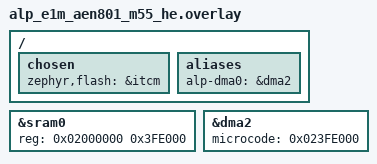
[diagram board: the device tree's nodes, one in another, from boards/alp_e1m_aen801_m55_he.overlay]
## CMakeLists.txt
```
# SPDX-License-Identifier: Apache-2.0
#
# aen-dma-regcheck -- on-silicon validation of the ARM PL330 DMA controller on
# the E1M-AEN801 (Alif Ensemble E8, M55-HE), via the bench RAM-run + RAM-console
# flow.  Unlike the bind-only *-regcheck siblings, this app runs a REAL
# memory-to-memory copy through the PL330 and verifies the bytes (the PL330 needs
# no external pins).
#
# The PL330 driver is UPSTREAM Zephyr v4.4's drivers/dma/dma_pl330.c
# (compatible "arm,dma-pl330") -- ADR 0017 Tier-1 (upstream-native), no vendored
# code.  CONFIG_DMA + CONFIG_DMA_PL330 (prj.conf) build it in once the dma2 node
# is enabled by the board overlay.  The overlay enables dma2, defines the
# alp_dma0 alias, points the PL330 `microcode` scratch at global SRAM0, and
# carves the source/destination buffers into SRAM0 (the PL330 AXI master cannot
# reach the M55's DTCM).
#
# The board overlay boards/alp_e1m_aen801_m55_he_ae822fa0e5597ls0_rtss_he.overlay auto-applies for the
# fully-qualified board (alp_e1m_aen801_m55_he/ae822fa0e5597ls0/rtss_he).  Build:
#   ZEPHYR_BASE=<zephyr-base> west build \
#     -b alp_e1m_aen801_m55_he/ae822fa0e5597ls0/rtss_he <this-dir> -- \
#     "-DEXTRA_ZEPHYR_MODULES=<alp-sdk>;<hal_alif>"

cmake_minimum_required(VERSION 3.20)

find_package(Zephyr REQUIRED HINTS $ENV{ZEPHYR_BASE})
project(aen_dma_regcheck LANGUAGES C)

target_sources(app PRIVATE src/main.c)
```

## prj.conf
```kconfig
# SPDX-License-Identifier: Apache-2.0
#
# Bench config for the DMA regcheck on the E1M-AEN801 (M55-HE).  The console is
# the E1M edge UART0 (Alif UART5, P3_4/P3_5, 115200 8N1); serial-less benches
# can fall back to the RAM console (see the console block below).

# DMA subsystem + the UPSTREAM ARM PL330 driver.  CONFIG_DMA makes the dma_*
# class available; CONFIG_DMA_PL330 is `default y if DT_HAS_ARM_DMA_PL330_ENABLED`
# (drivers/dma/Kconfig.dma_pl330) so the upstream dma_pl330.c TU builds in once
# the dma2 node is enabled by the board overlay.  ADR 0017 Tier-1 -- pure
# upstream, no ALP_SDK gating needed for the driver itself.
CONFIG_DMA=y
CONFIG_DMA_PL330=y

# 32-bit address path: the M55 + the PL330 register set are 32-bit, and the
# buffers/microcode live in the 32-bit-addressable global SRAM0 window.  Leave
# CONFIG_DMA_64BIT off (its default) so the driver does NOT require a
# `control_regs` reg-by-name on the node (that 36-bit AXI-add-control window is
# not declared here).
# CONFIG_DMA_64BIT is not set

# Coherency: the PL330 AXI master and the M55 must share ONE view of the SRAM0
# buffers + microcode with no cache maintenance.  CONFIG_DCACHE=n matches the
# eth_dwmac / NPU DMA-buffers-in-SRAM0 finding (the upstream PL330 driver issues
# no cache clean/invalidate around the transfer).
CONFIG_DCACHE=n

# Console: Alp UART console -- E1M edge UART0 (Alif UART5, P3_4/P3_5, 115200
# 8N1, NS16550), the E1M-AEN801 carrier console. The board _defconfig already
# selects it; we set it explicitly here so the example is self-describing.
CONFIG_SERIAL=y
CONFIG_CONSOLE=y
CONFIG_UART_CONSOLE=y
CONFIG_UART_INTERRUPT_DRIVEN=y
# Serial-less bench? Comment the four lines above and uncomment these to read
# 'ram_console_buf' over SWD instead:
# CONFIG_RAM_CONSOLE=y
# CONFIG_RAM_CONSOLE_BUFFER_SIZE=2048
# CONFIG_UART_CONSOLE=n
CONFIG_PRINTK=y

# Keep the image small + deterministic for a RAM-run.
CONFIG_LOG=n
```

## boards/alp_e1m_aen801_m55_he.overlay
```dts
/*
 * Copyright (c) 2026 Alp Lab AB
 * SPDX-License-Identifier: Apache-2.0
 *
 * aen-dma-regcheck board overlay for the E1M-AEN801 (Ensemble E8, M55-HE)
 * RAM-run.  Enables the ARM PL330 DMA controller (dma2) that the E8 SoC overlay
 * (zephyr/dts/alif/ensemble_e8_peripherals.dtsi) declares status=disabled, binds
 * the alp_dma0 portable alias to it, gives the PL330 a real `microcode` scratch
 * address in global SRAM0, and reserves that SRAM0 carve-out so it cannot
 * collide with the source/destination buffers.
 *
 * ====================  DMA REACHABILITY: GLOBAL SRAM0 ONLY  ==================
 * The PL330 is an AXI bus master.  It fetches its generated per-channel
 * microcode AND reads/writes the copy buffers over its OWN AXI master, so EVERY
 * address it touches must be GLOBAL (AXI-visible).  The M55's DTCM (local
 * 0x20000000, where the generated board puts default RAM) is core-private and is
 * NOT on the DMA path.  So:
 *
 *   - the buffers (src_buf/dst_buf) are tagged section("SRAM0") in main.c, which
 *     lands them in the sram0 linker region @0x02000000 (global on-chip SRAM);
 *   - the PL330 `microcode` scratch is pointed at a carve-out at the TOP of that
 *     same 4 MiB bank.
 *
 * Unlike the NPU/eth paths, the UPSTREAM PL330 driver does NO Alif local->global
 * remap -- it programs the addresses verbatim -- so the addresses the CPU hands
 * it (the &src_buf/&dst_buf in SRAM0, and this `microcode` base) ARE the global
 * addresses the engine fetches.  Combined with CONFIG_DCACHE=n (prj.conf) the
 * CPU and DMA share one coherent view.
 *
 * SRAM0 CARVE-OUT (sram0 node = 0x02000000, DT_SIZE_M(4) = 0x400000):
 *   - microcode region : top 8 KiB = 0x023FE000 .. 0x02400000
 *                        (8 channels * MICROCODE_SIZE_MAX 0x400 = 0x2000, the
 *                         minimum the PL330 driver carves -- dma_pl330.h);
 *   - buffers (SRAM0)  : the sram0 node is SHRUNK to 0x02000000 + 0x3FE000
 *                        (4 MiB - 8 KiB) so the linker keeps src_buf/dst_buf
 *                        strictly BELOW the microcode region -- no overlap.
 * ============================================================================
 */

/ {
	/*
	 * MANDATORY bench RAM-run retarget (Flow C): run from ITCM so J-Link can
	 * loadbin+go without programming MRAM, and drop the MCUboot code-partition
	 * fixup.  Same setup as the sibling *-regcheck examples.
	 *
	 * PATH-REFERENCE form (&itcm), NOT the <&itcm> phandle-array form: the
	 * phandle-array form yields CONFIG_FLASH_SIZE=0 and the image overflows the
	 * (empty) FLASH region at link time.
	 */
	chosen {
		zephyr,flash = &itcm;
		/delete-property/ zephyr,code-partition;
	};

	aliases {
		/* The alp portable DMA alias resolves bus 0 via DT_ALIAS(alp_dma0). */
		alp-dma0 = &dma2;
	};
};

/*
 * Shrink the global SRAM0 region by the top 8 KiB so the PL330 microcode
 * carve-out (0x023FE000..0x02400000) never overlaps the section("SRAM0")
 * buffers.  Base stays 0x02000000; size 0x400000 - 0x2000 = 0x3FE000.
 */
&sram0 {
	reg = <0x02000000 0x3FE000>;
};

&dma2 {
	/*
	 * Real microcode scratch base: top 8 KiB of SRAM0 (global, AXI-visible),
	 * just above the shrunk sram0 region.  The PL330 driver carves this into
	 * 8 * 0x400 B per-channel ucode slots (dma_pl330_initialize()).
	 */
	microcode = <0x023FE000>;
	status = "okay";
};
```

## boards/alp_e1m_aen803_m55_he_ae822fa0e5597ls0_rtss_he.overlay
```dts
/*
 * Copyright (c) 2026 Alp Lab AB
 * SPDX-License-Identifier: Apache-2.0
 *
 * aen-dma-regcheck board overlay for the E1M-AEN803 (Ensemble E8, M55-HE)
 * RAM-run.  Enables the ARM PL330 DMA controller (dma2) that the E8 SoC overlay
 * (zephyr/dts/alif/ensemble_e8_peripherals.dtsi) declares status=disabled, binds
 * the alp_dma0 portable alias to it, gives the PL330 a real `microcode` scratch
 * address in global SRAM0, and reserves that SRAM0 carve-out so it cannot
 * collide with the source/destination buffers.
 *
 * ====================  DMA REACHABILITY: GLOBAL SRAM0 ONLY  ==================
 * The PL330 is an AXI bus master.  It fetches its generated per-channel
 * microcode AND reads/writes the copy buffers over its OWN AXI master, so EVERY
 * address it touches must be GLOBAL (AXI-visible).  The M55's DTCM (local
 * 0x20000000, where the generated board puts default RAM) is core-private and is
 * NOT on the DMA path.  So:
 *
 *   - the buffers (src_buf/dst_buf) are tagged section("SRAM0") in main.c, which
 *     lands them in the sram0 linker region @0x02000000 (global on-chip SRAM);
 *   - the PL330 `microcode` scratch is pointed at a carve-out at the TOP of that
 *     same 4 MiB bank.
 *
 * Unlike the NPU/eth paths, the UPSTREAM PL330 driver does NO Alif local->global
 * remap -- it programs the addresses verbatim -- so the addresses the CPU hands
 * it (the &src_buf/&dst_buf in SRAM0, and this `microcode` base) ARE the global
 * addresses the engine fetches.  Combined with CONFIG_DCACHE=n (prj.conf) the
 * CPU and DMA share one coherent view.
 *
 * SRAM0 CARVE-OUT (sram0 node = 0x02000000, DT_SIZE_M(4) = 0x400000):
 *   - microcode region : top 8 KiB = 0x023FE000 .. 0x02400000
 *                        (8 channels * MICROCODE_SIZE_MAX 0x400 = 0x2000, the
 *                         minimum the PL330 driver carves -- dma_pl330.h);
 *   - buffers (SRAM0)  : the sram0 node is SHRUNK to 0x02000000 + 0x3FE000
 *                        (4 MiB - 8 KiB) so the linker keeps src_buf/dst_buf
 *                        strictly BELOW the microcode region -- no overlap.
 * ============================================================================
 */

/ {
	/*
	 * MANDATORY bench RAM-run retarget (Flow C): run from ITCM so J-Link can
	 * loadbin+go without programming MRAM, and drop the MCUboot code-partition
	 * fixup.  Same setup as the sibling *-regcheck examples.
	 *
	 * PATH-REFERENCE form (&itcm), NOT the <&itcm> phandle-array form: the
	 * phandle-array form yields CONFIG_FLASH_SIZE=0 and the image overflows the
	 * (empty) FLASH region at link time.
	 */
	chosen {
		zephyr,flash = &itcm;
		/delete-property/ zephyr,code-partition;
	};

	aliases {
		/* The alp portable DMA alias resolves bus 0 via DT_ALIAS(alp_dma0). */
		alp-dma0 = &dma2;
	};
};

/*
 * Shrink the global SRAM0 region by the top 8 KiB so the PL330 microcode
 * carve-out (0x023FE000..0x02400000) never overlaps the section("SRAM0")
 * buffers.  Base stays 0x02000000; size 0x400000 - 0x2000 = 0x3FE000.
 */
&sram0 {
	reg = <0x02000000 0x3FE000>;
};

&dma2 {
	/*
	 * Real microcode scratch base: top 8 KiB of SRAM0 (global, AXI-visible),
	 * just above the shrunk sram0 region.  The PL330 driver carves this into
	 * 8 * 0x400 B per-channel ucode slots (dma_pl330_initialize()).
	 */
	microcode = <0x023FE000>;
	status = "okay";
};
```

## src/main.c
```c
/*
 * Copyright (c) 2026 Alp Lab AB
 * SPDX-License-Identifier: Apache-2.0
 *
 * aen-dma-regcheck -- on-silicon validation of the ARM PL330 DMA controller on
 * the E1M-AEN801 (Ensemble E8, M55-HE), via the bench RAM-run + RAM-console
 * flow.  Unlike the bind-only *-regcheck siblings (CAN/camera/ISP, which are
 * HW-blocked on missing wiring), this app performs a REAL memory-to-memory copy:
 * the PL330 needs no external pins or transceiver, so it actually runs the DMA
 * and verifies the bytes landed.
 *
 * ===========================  WHAT THIS VALIDATES  ==========================
 *   1. The dma2 DT node binds to UPSTREAM Zephyr's ARM PL330 driver
 *      (drivers/dma/dma_pl330.c, compatible "arm,dma-pl330") at the E8's
 *      core-local secure DMA2 base 0x400C0000 -- pure ADR 0017 Tier-1
 *      (upstream-native): the standard Zephyr dma_* class device, no vendored
 *      or forked code.
 *   2. The alp portable alias alp_dma0 resolves to that same node.
 *   3. The driver INSTANTIATES (DEVICE_DT_GET resolves, device_is_ready()).
 *   4. A real M2M transfer COPIES the bytes: dma_config(MEMORY_TO_MEMORY) +
 *      dma_start(), then a memcmp() of source vs destination.
 *
 * The upstream PL330 driver is a POLLING engine: dma_pl330_transfer_start()
 * calls dma_pl330_submit() -> dma_pl330_xfer() -> dma_pl330_wait(), which spins
 * on the channel-status CS0 register until the channel goes idle.  So when
 * dma_start() RETURNS 0 the copy has already completed -- no interrupt and no
 * completion callback are needed (and the binding declares no `interrupts`).
 * That is why this app verifies synchronously right after dma_start().
 *
 * ====================  THE #1 BENCH RISK: DMA REACHABILITY  =================
 * The PL330 is an AXI bus master.  It fetches its generated channel microcode
 * AND reads/writes the source/destination buffers over its OWN AXI master, so
 * EVERY address it touches must be a GLOBAL (AXI-visible) address -- NOT a
 * core-local TCM alias.  The M55's default RAM (.bss/.noinit) on the generated
 * board lands in DTCM (local 0x20000000), which the DMA AXI master cannot see.
 *
 * Fix (mirrors the eth_dwmac DMA-buffers-in-SRAM0 + the NPU arena-in-SRAM0
 * findings): src_buf/dst_buf are tagged into the "SRAM0" linker region -- global
 * on-chip SRAM @0x02000000 -- and the board overlay points the PL330 `microcode`
 * scratch at a carve-out in that same bank.  Combined with CONFIG_DCACHE=n
 * (prj.conf) the CPU and the DMA share one coherent view with no cache
 * maintenance.  If the buffers were left in DTCM the copy would read/write
 * garbage or fault; placing them in global SRAM0 is what makes the transfer
 * real.  See the board overlay header for the carve-out addresses.
 * ============================================================================
 */

#include <stdbool.h>
#include <stdint.h>
#include <string.h>

#include <zephyr/kernel.h>
#include <zephyr/device.h>
#include <zephyr/devicetree.h>
#include <zephyr/drivers/dma.h>
#include <zephyr/sys/printk.h>
#include <zephyr/sys/sys_io.h>

/* The PL330 controller node + the alp portable alias that must point at it. */
#define DMA_NODE  DT_NODELABEL(dma2)
#define DMA_ALIAS DT_ALIAS(alp_dma0)

/* Channel 0 of the 8 PL330 execution channels (dma-channels = <8>). */
#define DMA_CHANNEL 0U

/* Transfer size.  Deliberately not a multiple of the burst length so the
 * driver's residual-tail path is exercised too. */
#define XFER_LEN 1000U

/*
 * Expected facts, transcribed from the SoC dtsi (which carries the Alif AE822
 * DFP addresses) so a binding that resolved to the wrong node is caught.
 *
 *   reg base 0x400C0000 -- DMA2_SEC_BASE (DFP rtss_he/soc.h)
 *   dma-channels 8      -- PL330 execution channels (DFP DMA_*_CHANNEL_*[8])
 */
#define DMA_BASE_EXPECTED     0x400C0000U
#define DMA_CHANNELS_EXPECTED 8U

/*
 * Source + destination buffers MUST be in global, AXI-visible SRAM0 (see the
 * file + overlay headers): the PL330 AXI master cannot reach the M55's DTCM.
 * The "SRAM0" section is the sram0 node's linker region (@0x02000000).
 */
static uint8_t src_buf[XFER_LEN] __attribute__((section("SRAM0")));
static uint8_t dst_buf[XFER_LEN] __attribute__((section("SRAM0")));

/*
 * Compile-time staging fact: the node exists, is enabled, and binds to the
 * upstream PL330 compatible.
 */
#define DMA_BOUND \
	(DT_NODE_HAS_STATUS(DMA_NODE, okay) && DT_NODE_HAS_COMPAT(DMA_NODE, arm_dma_pl330))

/* The alp_dma0 alias must resolve to the SAME node the PL330 driver binds. */
#define ALIAS_OK (DT_NODE_EXISTS(DMA_ALIAS) && (DT_DEP_ORD(DMA_ALIAS) == DT_DEP_ORD(DMA_NODE)))

int main(void)
{
	printk("\n=== aen-dma-regcheck ===\n");

	/*
	 * Alif E8 prelude: DMA2 is the M55-core-LOCAL DMA.  The upstream
	 * arm,dma-pl330 driver is SoC-agnostic and never touches the Alif system-
	 * control block, so before it can run we have to do here exactly what the
	 * Alif CMSIS DMA driver does in its power-up path (DFP Driver_DMA.c
	 * DMA_PowerControl ARM_POWER_FULL, case DMA_INSTANCE_LOCAL):
	 *
	 *   (1) dmalocal_enable_periph_clk()        CLK_ENA   |= BIT(4)
	 *   (2) dmalocal_set_boot_manager_secure()  DMA_CTRL  &= ~BIT(0)   (0 = secure)
	 *   (3) dmalocal_set_boot_irq_ns_mask(0)    DMA_IRQ    = 0
	 *   (4) dmalocal_set_boot_periph_ns_mask(0) DMA_PERIPH = 0
	 *   (5) dmalocal_reset()                    DMA_CTRL  |= BIT(16)   (SW_RST)
	 *
	 * These registers live in the per-core M55_CFG_Common block.  On the M55-HE
	 * that block IS M55HE_CFG (DFP rtss_he/core_defines.h:
	 * M55LOCAL_CFG == (M55_CFG_Common_Type *)M55HE_CFG_BASE).  Clean-room values
	 * transcribed from the DFP (proprietary; values only, not source):
	 *   M55HE_CFG_BASE        0x43007000  -- DFP rtss_he/soc.h
	 *   DMA_CTRL    @ +0x00 |   DMA_IRQ @ +0x04 |  DMA_PERIPH @ +0x08
	 *   DMA_SEL     @ +0x0C |   CLK_ENA @ +0x10   -- DFP M55_CFG_Common_Type
	 *                                                (rtss_he/core_defines.h)
	 *   CLK_ENA_DMA_CKEN      BIT(4)       -- DFP drivers/include/sys_ctrl_dma.h
	 *   DMA_CTRL_BOOT_MANAGER BIT(0)  0=Secure 1=Non-Secure -- DFP sys_ctrl_dma.h
	 *   DMA_CTRL_SW_RST       BIT(16)      -- DFP drivers/include/sys_ctrl_dma.h
	 * Boot IRQ / boot peripheral non-secure masks are 0 (RTE_DMA2_BOOT_IRQ_NS_STATE
	 * / RTE_DMA2_BOOT_PERIPH_NS_STATE == 0 for AE822, DFP soc/AE822.../rte/
	 * RTE_Device.h) -- everything stays in the secure domain, matching the secure
	 * DMA2 base 0x400C0000 (DMA2_SEC_BASE) the M55-HE uses on the secure RAM-run.
	 *
	 * WHY the M2M copy did not land before this fix (clock-only prelude):
	 * step (1) alone clears the bus fault and lets the driver bind, but the PL330
	 * manager samples its boot security pins (boot_manager_ns / boot_irq_ns[] /
	 * boot_peripheral_ns[]) ONLY out of reset, from DMA_CTRL[0] / DMA_IRQ /
	 * DMA_PERIPH.  The upstream driver launches channel 0 with a *secure* DMAGO
	 * (DBGINST0 ns bit clear, since ch_handle->nonsec_mode == 0).  Per the ARM
	 * DMA-330 TRM a DMAGO that requests a security state the manager has not
	 * booted into is treated as DMANOP -- accepted with no fault, but the channel
	 * thread never starts.  That is exactly the observed signature: DBGCMD goes
	 * idle, FSRD/FSRC/FTR0 == 0, yet CS0 == STOP and SA0/DA0/CPC0 == 0 (channel
	 * never programmed).  Writing the secure boot config in (2)-(4) and then
	 * pulsing SW_RST in (5) re-boots the manager into the secure domain so the
	 * secure DMAGO is honoured and the channel executes the generated microcode.
	 *
	 * TODO: fold this into the Tier-1.5 clockctrl so the device is clocked
	 * and boot-configured by its DT `clocks` phandle instead of an app-level poke.
	 */
#define M55HE_CFG_DMA_CTRL    0x43007000U /* M55_CFG_Common.DMA_CTRL   (+0x00) */
#define M55HE_CFG_DMA_IRQ     0x43007004U /* M55_CFG_Common.DMA_IRQ    (+0x04) */
#define M55HE_CFG_DMA_PERIPH  0x43007008U /* M55_CFG_Common.DMA_PERIPH (+0x08) */
#define M55HE_CFG_CLK_ENA     0x43007010U /* M55_CFG_Common.CLK_ENA    (+0x10) */
#define CLK_ENA_DMA_CKEN      BIT(4)      /* DFP CLK_ENA_DMA_CKEN              */
#define DMA_CTRL_BOOT_MANAGER BIT(0)      /* DFP DMA_CTRL_BOOT_MANAGER 0=Sec   */
#define DMA_CTRL_SW_RST       BIT(16)     /* DFP DMA_CTRL_SW_RST               */

	/* (1) ungate the DMA2 local peripheral clock. */
	sys_write32(sys_read32(M55HE_CFG_CLK_ENA) | CLK_ENA_DMA_CKEN, M55HE_CFG_CLK_ENA);

	/* (2) boot the PL330 manager SECURE (clear BOOT_MANAGER), matching the
	 * secure DMA2 base and the driver's secure DMAGO. */
	sys_write32(sys_read32(M55HE_CFG_DMA_CTRL) & ~DMA_CTRL_BOOT_MANAGER, M55HE_CFG_DMA_CTRL);

	/* (3)+(4) all boot IRQs and peripheral request lines stay secure. */
	sys_write32(0U, M55HE_CFG_DMA_IRQ);
	sys_write32(0U, M55HE_CFG_DMA_PERIPH);

	/* (5) pulse SW_RST so the manager re-samples the secure boot config above. */
	sys_write32(sys_read32(M55HE_CFG_DMA_CTRL) | DMA_CTRL_SW_RST, M55HE_CFG_DMA_CTRL);

	printk("prelude: DMA2 local clock+secure-boot configured "
	       "(CLK_ENA|=BIT4, DMA_CTRL secure-mgr, DMA_IRQ=DMA_PERIPH=0, SW_RST)\n");

	/*
	 * Step 1+2: report the node's binding + reg base + channel count.  These are
	 * build-time constants pulled from the bound node; a mismatch vs the DFP
	 * address means the binding resolved to the wrong node.
	 */
	uint32_t dma_base     = (uint32_t)DT_REG_ADDR(DMA_NODE);
	uint32_t dma_channels = (uint32_t)DT_PROP(DMA_NODE, dma_channels);

	printk("dma2  : %s\n", DT_NODE_FULL_NAME(DMA_NODE));
	printk("        bound=%d compat=arm,dma-pl330 base=0x%08x (exp 0x%08x) channels=%u (exp %u)\n",
	       (int)DMA_BOUND,
	       dma_base,
	       DMA_BASE_EXPECTED,
	       dma_channels,
	       DMA_CHANNELS_EXPECTED);
	printk("alias : alp_dma0 -> %s (resolves_to_dma2=%d)\n",
	       DT_NODE_FULL_NAME(DMA_ALIAS),
	       (int)ALIAS_OK);

	/*
	 * Step 3: probe the instantiated driver.  DEVICE_DT_GET resolves at build
	 * time; device_is_ready() reports the PL330 init result (it only sets up the
	 * per-channel mcode_base + mutexes -- no bus access at init).
	 */
	const struct device *dma_dev = DEVICE_DT_GET(DMA_NODE);
	bool                 ready   = device_is_ready(dma_dev);

	printk("dma2  device : %s\n",
	       ready ? "READY (arm,dma-pl330 driver instantiated)" : "NOT ready (init failed)");

	/*
	 * Step 4: the real work -- a memory-to-memory copy through the PL330.
	 *
	 * Fill the source with a known ramp, clear the destination, then ask the
	 * DMA to copy.  The driver's M2M path reads only head_block's source/dest
	 * addresses, block_size, and the addr-adj modes (both INCREMENT for a
	 * straight copy); source/dest_data_size + burst_length are advisory (the
	 * driver computes its own burst geometry from the addresses + size).
	 */
	for (uint32_t i = 0; i < XFER_LEN; i++) {
		src_buf[i] = (uint8_t)(i + 1U);
	}
	memset(dst_buf, 0, sizeof(dst_buf));

	struct dma_block_config blk = {
		.source_address  = (uint32_t)(uintptr_t)src_buf,
		.dest_address    = (uint32_t)(uintptr_t)dst_buf,
		.block_size      = XFER_LEN,
		.source_addr_adj = DMA_ADDR_ADJ_INCREMENT,
		.dest_addr_adj   = DMA_ADDR_ADJ_INCREMENT,
	};
	struct dma_config cfg = {
		.channel_direction   = MEMORY_TO_MEMORY,
		.source_data_size    = 1,
		.dest_data_size      = 1,
		.source_burst_length = 1,
		.dest_burst_length   = 1,
		.block_count         = 1,
		.head_block          = &blk,
	};

	bool xfer_ok  = false;
	int  rc_cfg   = -1;
	int  rc_start = -1;

	if (ready) {
		rc_cfg = dma_config(dma_dev, DMA_CHANNEL, &cfg);
		if (rc_cfg == 0) {
			/*
			 * Synchronous on the PL330 polling driver: when dma_start()
			 * returns 0 the channel has already gone idle (dma_pl330_wait
			 * polled CS0), so the copy is complete and we can verify now.
			 */
			rc_start = dma_start(dma_dev, DMA_CHANNEL);
			if (rc_start == 0) {
				xfer_ok = (memcmp(src_buf, dst_buf, XFER_LEN) == 0);
			}
		}
	}

	printk("xfer  : dma_config rc=%d dma_start rc=%d memcmp_match=%d (%u bytes M2M)\n",
	       rc_cfg,
	       rc_start,
	       (int)xfer_ok,
	       XFER_LEN);

	/*
	 * Diagnostic: dump the PL330 manager + channel-0 status after the transfer.
	 * Standard ARM PL330 (DMA-330) register offsets (ARM DDI 0424 TRM):
	 *   DSR  +0x000 manager status   DPC  +0x004 manager PC
	 *   FSRD +0x030 fault-status mgr  FSRC +0x034 fault-status chan (bit n = chan n)
	 *   FTRD +0x038 fault-type  mgr   FTR0 +0x040 fault-type  chan0
	 *   CS0  +0x100 chan0 status (bits[3:0] state: 0=STOP 1=EXEC 7=WFE Eh=FAULTING Fh=FLT_COMPLETING)
	 *   CPC0 +0x104 chan0 PC          SA0  +0x400 src addr     DA0 +0x404 dst addr
	 * A faulting channel (CS0[3:0]=Eh/Fh, FSRC bit0=1) explains a clean dma_start
	 * return with no bytes moved: the upstream polling driver treats "not running"
	 * as done. CPC0 + FTR0 localize WHERE/WHY it stopped.
	 */
	const uint32_t pl330 = DMA_BASE_EXPECTED;

	printk("pl330 : DSR=%08x DPC=%08x FSRD=%08x FSRC=%08x FTRD=%08x FTR0=%08x\n",
	       sys_read32(pl330 + 0x000),
	       sys_read32(pl330 + 0x004),
	       sys_read32(pl330 + 0x030),
	       sys_read32(pl330 + 0x034),
	       sys_read32(pl330 + 0x038),
	       sys_read32(pl330 + 0x040));
	printk("pl330 : CS0=%08x CPC0=%08x SA0=%08x DA0=%08x\n",
	       sys_read32(pl330 + 0x100),
	       sys_read32(pl330 + 0x104),
	       sys_read32(pl330 + 0x400),
	       sys_read32(pl330 + 0x404));

	/*
	 * PASS gate: the PL330 BINDS (dma2 -> arm,dma-pl330 at 0x400C0000 with 8
	 * channels), the alp_dma0 alias points at it, the driver is ready, AND a real
	 * memory-to-memory copy moved every byte (memcmp match).  This is a genuine
	 * end-to-end transfer, not a bind-only staging check.
	 */
	bool pass = DMA_BOUND && (dma_base == DMA_BASE_EXPECTED) &&
	            (dma_channels == DMA_CHANNELS_EXPECTED) && ALIAS_OK && ready && xfer_ok;

	if (pass) {
		printk("RESULT PASS: PL330 DMA WORKS -- dma2 binds to arm,dma-pl330 at 0x%08x "
		       "(%u channels), alp_dma0 alias points at it, and a %u-byte memory-to-memory "
		       "copy through channel %u verified byte-for-byte (src/dst in global SRAM0)\n",
		       DMA_BASE_EXPECTED,
		       DMA_CHANNELS_EXPECTED,
		       XFER_LEN,
		       DMA_CHANNEL);
	} else {
		printk("RESULT FAIL: PL330 DMA NOT validated "
		       "(bound=%d base=%d channels=%d alias=%d ready=%d xfer=%d -- a fact is "
		       "missing, the node bound to the wrong compatible/reg base, or the M2M "
		       "copy did not complete; if bind is OK but xfer failed, check that the "
		       "buffers + microcode are in global SRAM0, not DTCM)\n",
		       (int)DMA_BOUND,
		       (int)(dma_base == DMA_BASE_EXPECTED),
		       (int)(dma_channels == DMA_CHANNELS_EXPECTED),
		       (int)ALIAS_OK,
		       (int)ready,
		       (int)xfer_ok);
	}

	return 0;
}
```
